# RA2A1 register map
Vendor: Renesas Electronics Corporation; Series: RA2; File version: 1.1
CPU: other r1p0, little endian, MPU, no FPU, VTOR, 2 interrupt priority bits
Registers are 8-bit, read-write, reset 0x0 unless marked. A register's access mark holds for its fields unless they carry their own. Offsets are from the block's base; [hi:lo] are bit positions; 'fields as' and 'values as' point back to an identical list.

## MSTP — Module Stop Control B,C,D
Base 0x40047000
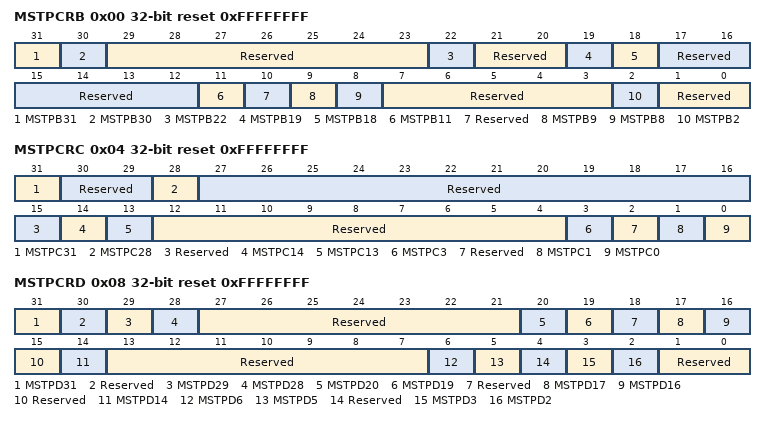
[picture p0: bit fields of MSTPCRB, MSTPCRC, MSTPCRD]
0x00 MSTPCRB 32-bit reset 0xFFFFFFFF — Module Stop Control Register B
  [31] MSTPB31 — Serial Communication Interface 0 Module Stop
    0=Cancel the module-stop state; 1=Enter the module-stop state
  [30] MSTPB30 — Serial Communication Interface 1 Module Stop
    values as MSTPB31
  [29:23] Reserved — These bits are read as 1111111. The write value should be 1111111.
  [22] MSTPB22 — Serial Communication Interface 9 Module Stop
    values as MSTPB31
  [21:20] Reserved — These bits are read as 11. The write value should be 11.
  [19] MSTPB19 — Serial Peripheral Interface 0 Module Stop
    values as MSTPB31
  [18] MSTPB18 — Serial Peripheral Interface 1 Module Stop
    values as MSTPB31
  [17:12] Reserved — These bits are read as 111111. The write value should be 111111.
  [11] MSTPB11 — Universal Serial Bus 2.0 FS Interface Module Stop
    values as MSTPB31
  [10] Reserved — This bit is read as 1. The write value should be 1.
  [9] MSTPB9 — I2C Bus Interface 0 Module Stop
    values as MSTPB31
  [8] MSTPB8 — I2C Bus Interface 1 Module Stop
    values as MSTPB31
  [7:3] Reserved — These bits are read as 11111. The write value should be 11111.
  [2] MSTPB2 — CAN0 Module Stop
    values as MSTPB31
  [1:0] Reserved — These bits are read as 11. The write value should be 11.
0x04 MSTPCRC 32-bit reset 0xFFFFFFFF — Module Stop Control Register C
  [31] MSTPC31 — AES Module Stop
    values as MSTPCRB.MSTPB31
  [30:29] Reserved — These bits are read as 11. The write value should be 11.
  [28] MSTPC28 — Random Number Generator Module Stop
    values as MSTPCRB.MSTPB31
  [27:15] Reserved — These bits are read as 1111111111111. The write value should be 1111111111111.
  [14] MSTPC14 — Event Link Controller Module Stop
    values as MSTPCRB.MSTPB31
  [13] MSTPC13 — Data Operation Circuit Module Stop
    values as MSTPCRB.MSTPB31
  [12:4] Reserved — These bits are read as 111111111. The write value should be 111111111.
  [3] MSTPC3 — Capacitive Touch Sensing Unit Module Stop
    values as MSTPCRB.MSTPB31
  [2] Reserved — This bit is read as 1. The write value should be 1.
  [1] MSTPC1 — CRC Calculator Module Stop
    values as MSTPCRB.MSTPB31
  [0] MSTPC0 — CAC Module Stop
    values as MSTPCRB.MSTPB31
0x08 MSTPCRD 32-bit reset 0xFFFFFFFF — Module Stop Control Register D
  [31] MSTPD31 — Operational Amplifier Module Stop
    values as MSTPCRB.MSTPB31
  [30] Reserved — This bit is read as 1. The write value should be 1.
  [29] MSTPD29 — Comparator-LP Module Stop
    values as MSTPCRB.MSTPB31
  [28] MSTPD28 — ACMPHS0 Module Stop
    values as MSTPCRB.MSTPB31
  [27:21] Reserved — These bits are read as 1111111. The write value should be 1111111.
  [20] MSTPD20 — 12-bit D/A Converter Module Stop
    values as MSTPCRB.MSTPB31
  [19] MSTPD19 — 8-Bit D/A Converter Module Stop
    values as MSTPCRB.MSTPB31
  [18] Reserved — This bit is read as 1. The write value should be 1.
  [17] MSTPD17 — 24-bit Sigma-Delta A/DConverter Module Stop
    values as MSTPCRB.MSTPB31
  [16] MSTPD16 — 16-Bit A/D Converter Module Stop
    values as MSTPCRB.MSTPB31
  [15] Reserved — This bit is read as 1. The write value should be 1.
  [14] MSTPD14 — POEG Module Stop
    values as MSTPCRB.MSTPB31
  [13:7] Reserved — These bits are read as 1111111. The write value should be 1111111.
  [6] MSTPD6 — GPT ch6 - ch1 Module Stop
    values as MSTPCRB.MSTPB31
  [5] MSTPD5 — GPT ch0 Module Stop
    values as MSTPCRB.MSTPB31
  [4] Reserved — This bit is read as 1. The write value should be 1.
  [3] MSTPD3 — AGT0 Module StopNote: AGT0 is in the module stop state when the count source is either of PCLKB, PCLKB/2 or PCLKB/8. In case the count source is sub-clock or LOCO, this bit should be set to 1 except when accessing the registers of AGT0.
    values as MSTPCRB.MSTPB31
  [2] MSTPD2 — AGT1 Module StopNote: AGT1 is in the module stop state when the count source is either of PCLKB, PCLKB/2 or PCLKB/8. In case the count source is sub-clock or LOCO, this bit should be set to 1 except when accessing the registers of AGT1.
    values as MSTPCRB.MSTPB31
  [1:0] Reserved — These bits are read as 11. The write value should be 11.
